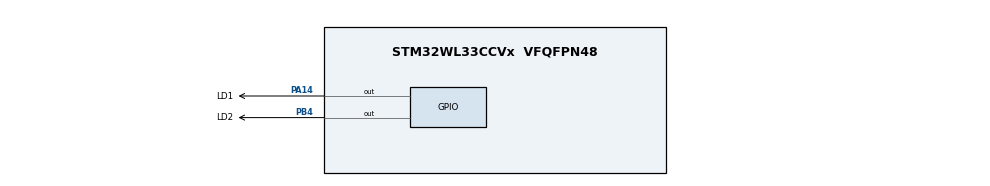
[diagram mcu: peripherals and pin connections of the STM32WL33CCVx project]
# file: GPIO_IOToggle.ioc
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Mcu.Family=STM32WL3
Mcu.Name=STM32WL33CCVx
Mcu.Package=VFQFPN48
OSCIN.Mode=HSE-External-Oscillator
OSCIN.Signal=RCC_OSC_IN
OSCOUT.Mode=HSE-External-Oscillator
OSCOUT.Signal=RCC_OSC_OUT
PA14.GPIO_Label=LD1
PA14.GPIO_Speed=GPIO_SPEED_FREQ_HIGH
PA14.Signal=GPIO_Output
PB4.GPIO_Label=LD2
PB4.GPIO_Speed=GPIO_SPEED_FREQ_HIGH
PB4.Signal=GPIO_Output
ProjectManager.HeapSize=0x000
ProjectManager.StackSize=0xC00
ProjectManager.TargetToolchain=EWARM V9.30
RCC.HSE_VALUE=48000000
RCC.HSI_VALUE=64000000
RCC.LSE_VALUE=32768
RCC.RC64MPLLSource=RCC_LSCOSOURCE_PLL64
VP_PWR_VS_SECSignals.Mode=Security/Privilege
board=custom

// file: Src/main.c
/* USER CODE BEGIN Header */
/**
  ******************************************************************************
  * @file    GPIO/GPIO_IOToggle/Src/main.c
  * @author  MCD Application Team
  * @brief   This example describes how to configure and use GPIOs through
  *          the STM32WL3x HAL API.
  ******************************************************************************
  * @attention
  *
  * Copyright (c) 2024 STMicroelectronics.
  * All rights reserved.
  *
  * This software is licensed under terms that can be found in the LICENSE file
  * in the root directory of this software component.
  * If no LICENSE file comes with this software, it is provided AS-IS.
  *
  ******************************************************************************
  */
/* USER CODE END Header */
#include "main.h"

void SystemClock_Config(void);
void PeriphCommonClock_Config(void);
static void MX_GPIO_Init(void);

int main(void)
{

  /* USER CODE BEGIN 1 */
  /* STM32WL3x HAL library initialization:
       - Systick timer is configured by default as source of time base, but user
             can eventually implement his proper time base source (a general purpose
             timer for example or other time source), keeping in mind that Time base
             duration should be kept 1ms since PPP_TIMEOUT_VALUEs are defined and
             handled in milliseconds basis.
       - Set NVIC Group Priority to 4
       - Low Level Initialization
     */
  /* USER CODE END 1 */

  /* MCU Configuration--------------------------------------------------------*/

  /* Reset of all peripherals, Initializes the Flash interface and the Systick. */
  HAL_Init();

  /* Configure the system clock */
  SystemClock_Config();

  /* Configure the peripherals common clocks */
  PeriphCommonClock_Config();

  /* Initialize all configured peripherals */
  MX_GPIO_Init();

  /* Infinite loop */
  while (1)
  {

    /* USER CODE BEGIN 3 */
    HAL_GPIO_TogglePin(LD1_GPIO_Port, LD1_Pin);
    /* Insert delay 100 ms */
    HAL_Delay(100);
    HAL_GPIO_TogglePin(LD2_GPIO_Port, LD2_Pin);
    /* Insert delay 100 ms */
    HAL_Delay(100);

  }
  /* USER CODE END 3 */
}

void SystemClock_Config(void)
{
  RCC_OscInitTypeDef RCC_OscInitStruct = {0};
  RCC_ClkInitTypeDef RCC_ClkInitStruct = {0};

  /** Initializes the RCC Oscillators according to the specified parameters
  * in the RCC_OscInitTypeDef structure.
  */
  RCC_OscInitStruct.OscillatorType = RCC_OSCILLATORTYPE_HSE;
  RCC_OscInitStruct.HSEState = RCC_HSE_ON;
  if (HAL_RCC_OscConfig(&RCC_OscInitStruct) != HAL_OK)
  {
    Error_Handler();
  }

  /** Configure the SYSCLKSource and SYSCLKDivider
  */
  RCC_ClkInitStruct.SYSCLKSource = RCC_SYSCLKSOURCE_RC64MPLL;
  RCC_ClkInitStruct.SYSCLKDivider = RCC_RC64MPLL_DIV1;

  if (HAL_RCC_ClockConfig(&RCC_ClkInitStruct, FLASH_WAIT_STATES_1) != HAL_OK)
  {
    Error_Handler();
  }
}

void PeriphCommonClock_Config(void)
{
  RCC_PeriphCLKInitTypeDef PeriphClkInitStruct = {0};

  /** Initializes the peripherals clock
  */
  PeriphClkInitStruct.PeriphClockSelection = RCC_PERIPHCLK_SMPS;
  PeriphClkInitStruct.SmpsDivSelection = RCC_SMPSCLK_DIV2;
  PeriphClkInitStruct.KRMRateMultiplier = 2;

  if (HAL_RCCEx_PeriphCLKConfig(&PeriphClkInitStruct) != HAL_OK)
  {
    Error_Handler();
  }
}

static void MX_GPIO_Init(void)
{
  GPIO_InitTypeDef GPIO_InitStruct = {0};

  /* GPIO Ports Clock Enable */
  __HAL_RCC_GPIOB_CLK_ENABLE();
  __HAL_RCC_GPIOA_CLK_ENABLE();

  /*Configure GPIO pin Output Level */
  HAL_GPIO_WritePin(LD2_GPIO_Port, LD2_Pin, GPIO_PIN_RESET);

  /*Configure GPIO pin Output Level */
  HAL_GPIO_WritePin(LD1_GPIO_Port, LD1_Pin, GPIO_PIN_RESET);

  /*Configure GPIO pin : LD2_Pin */
  GPIO_InitStruct.Pin = LD2_Pin;
  GPIO_InitStruct.Mode = GPIO_MODE_OUTPUT_PP;
  GPIO_InitStruct.Pull = GPIO_NOPULL;
  GPIO_InitStruct.Speed = GPIO_SPEED_FREQ_HIGH;
  HAL_GPIO_Init(LD2_GPIO_Port, &GPIO_InitStruct);

  /*Configure GPIO pin : LD1_Pin */
  GPIO_InitStruct.Pin = LD1_Pin;
  GPIO_InitStruct.Mode = GPIO_MODE_OUTPUT_PP;
  GPIO_InitStruct.Pull = GPIO_NOPULL;
  GPIO_InitStruct.Speed = GPIO_SPEED_FREQ_HIGH;
  HAL_GPIO_Init(LD1_GPIO_Port, &GPIO_InitStruct);

  /**/
  HAL_PWREx_DisableGPIOPullUp(PWR_GPIO_B, PWR_GPIO_BIT_4);

  /**/
  HAL_PWREx_DisableGPIOPullUp(PWR_GPIO_A, PWR_GPIO_BIT_14);

  /**/
  HAL_PWREx_DisableGPIOPullDown(PWR_GPIO_B, PWR_GPIO_BIT_4);

  /**/
  HAL_PWREx_DisableGPIOPullDown(PWR_GPIO_A, PWR_GPIO_BIT_14);

}

void Error_Handler(void)
{
  while(1)
  {
  }
}
